# RA register map
Vendor: Renesas; Series: All Chips; File version: x.xx
Registers are 32-bit, read-write, reset 0x0 unless marked. A register's access mark holds for its fields unless they carry their own. Offsets are from the block's base; [hi:lo] are bit positions; lines under a group give offsets from that group; {n}, {i} and the like mark numbered series; 'fields as' and 'values as' point back to an identical list; <NAME> marks a mode.

## R_CANFD — Controller Area Network - Flexible Data (CAN-FD) Module
Base 0x400B0000
{0x0+0x10*i} CFDC[{i}] (i=0..1) group — Channel Control/Status
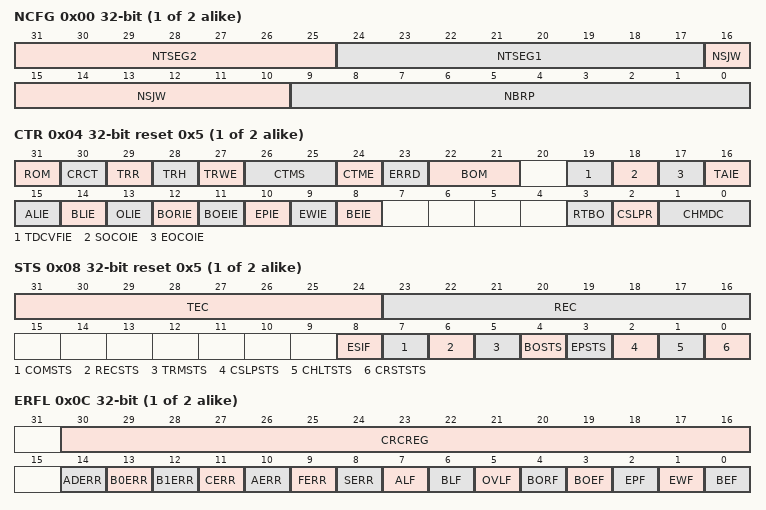
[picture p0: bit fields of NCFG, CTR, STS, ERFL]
  0x00 NCFG — Channel Nominal Bitrate Configuration Register
    [31:25] NTSEG2 — Timing Segment 2
    [24:17] NTSEG1 — Timing Segment 1
    [16:10] NSJW — Resynchronization Jump Width
    [9:0] NBRP — Channel Nominal Baud Rate Prescaler
  0x04 CTR reset 0x5 — Channel Control Registers
    [31] ROM — Restricted Operation Mode
      0=Restricted Operation Mode disabled; 1=Restricted Operation Mode enabled
    [30] CRCT — CRC Error Test
      0=First data bit of reception stream not inverted; 1=First data bit of reception stream inverted
    [29] TRR — TEC/REC Reset
      0=Error counter normal operation; 1=Error counter reset
    [28] TRH — TEC/REC Hold
      0=Error counter normal operation; 1=Error counter frozen
    [27] TRWE — TEC/REC Write Enable
      0=Error Counter write disabled; 1=Error Counter write enabled
    [26:25] CTMS — Channel Test Mode Select
      0=Basic test mode; 1=Listen-Only mode; 2=Self test mode 0 (External Loop back mode); 3=Self test mode 1 (Internal Loop back mode)
    [24] CTME — Channel Test Mode Enable
      0=Channel Test Mode disabled; 1=Channel Test Mode enabled
    [23] ERRD — Channel Error Display
      0=Only the 1st set of error codes displayed; 1=Accumulated error codes displayed
    [22:21] BOM — Channel Bus-Off Mode
      0=Normal mode (comply with ISO 11898-1); 1=Entry to Halt Mode automatically at Bus-Off start; 2=Entry to Halt Mode automatically at Bus-Off end; 3=Entry to Halt Mode (during Bus-Off Recovery Period) by S/W
    [19] TDCVFIE — Transceiver Delay Compensation Violation Interrupt enable
      0=Transceiver Delay Compensation Violation Interrupt disabled; 1=Transceiver Delay Compensation Violation Interrupt enabled
    [18] SOCOIE — Successful Occurrence Counter Overflow Interrupt enable
      0=Successful occurrence counter overflow interrupt disabled; 1=Successful occurrence counter overflow interrupt enabled
    [17] EOCOIE — Error occurrence counter overflow Interrupt enable
      0=Error occurrence counter overflow Interrupt disabled; 1=Error occurrence counter overflow Interrupt enabled
    [16] TAIE — Transmission abort Interrupt Enable
      0=TX abort Interrupt disabled; 1=TX abort Interrupt enabled
    [15] ALIE — Arbitration Lost Interrupt Enable
      0=Arbitration Lost Interrupt disabled; 1=Arbitration Lost Interrupt enabled
    [14] BLIE — Bus Lock Interrupt Enable
      0=Bus Lock Interrupt disabled; 1=Bus Lock Interrupt enabled
    [13] OLIE — Overload Interrupt Enable
      0=Overload Interrupt disabled; 1=Overload Interrupt enabled
    [12] BORIE — Bus-Off Recovery Interrupt Enable
      0=Bus-Off Recovery Interrupt disabled; 1=Bus-Off Recovery Interrupt enabled
    [11] BOEIE — Bus-Off Entry Interrupt Enable
      0=Bus-Off Entry Interrupt disabled; 1=Bus-Off Entry Interrupt enabled
    [10] EPIE — Error Passive Interrupt Enable
      0=Error Passive Interrupt disabled; 1=Error Passive Interrupt enabled
    [9] EWIE — Error Warning Interrupt Enable
      0=Error Warning Interrupt disabled; 1=Error Warning Interrupt enabled
    [8] BEIE — Bus Error Interrupt Enable
      0=Bus Error Interrupt disabled; 1=Bus Error Interrupt enabled
    [3] RTBO — Return from Bus-Off
      0=Channel is not forced to return from Bus-Off; 1=Channel is forced to return from Bus-Off
    [2] CSLPR — Channel Sleep Request
      0=Channel Sleep Request disabled; 1=Channel Sleep Request enabled
    [1:0] CHMDC — Channel Mode Control
      0=Channel Operation Mode request; 1=Channel Reset request; 2=Channel Halt request; 3=Keep current value
  0x08 STS reset 0x5 — Channel Status Registers
    [31:24] TEC — Transmission Error Count
    [23:16] REC ro — Reception Error Count
    [8] ESIF — Error State Indication Flag
      0=No CAN-FD message has been received with the ESI flag was set; 1=At least 1 CAN-FD message was received where the ESI flag was set
    [7] COMSTS ro — Channel Communication Status
      0=Channel is not ready for communication; 1=Channel is ready for communication
    [6] RECSTS ro — Channel Receive Status
      0=Channel is not receiving; 1=Channel is receiving
    [5] TRMSTS ro — Channel Transmit Status
      0=Channel is not transmitting; 1=Channel is transmitting
    [4] BOSTS ro — Channel Bus-Off Status
      0=Channel not in Bus-Off state; 1=Channel in Bus-Off state
    [3] EPSTS ro — Channel Error Passive Status
      0=Channel not in Error Passive state; 1=Channel in Error Passive state
    [2] CSLPSTS ro — Channel SLEEP Status
      0=Channel not in Sleep Mode; 1=Channel in Sleep Mode
    [1] CHLTSTS ro — Channel HALT Status
      0=Channel not in Halt Mode; 1=Channel in Halt Mode
    [0] CRSTSTS ro — Channel RESET Status
      0=Channel not in Reset Mode; 1=Channel in Reset Mode
  0x0C ERFL — Channel Error Flag Registers
    [30:16] CRCREG ro — CRC Register value
    [14] ADERR — Acknowledge Delimiter Error
      0=Channel Ack Del Error not detected; 1=Channel Ack Del Error detected
    [13] B0ERR — Bit 0 Error
      0=Channel Bit 0 Error not detected; 1=Channel Bit 0 Error detected
    [12] B1ERR — Bit 1 Error
      0=Channel Bit 1 Error not detected; 1=Channel Bit 1 Error detected
    [11] CERR — CRC Error
      0=Channel CRC Error not detected; 1=Channel CRC Error detected
    [10] AERR — Acknowledge Error
      0=Channel Ack Error not detected; 1=Channel Ack Error detected
    [9] FERR — Form Error
      0=Channel Form Error not detected; 1=Channel Form Error detected
    [8] SERR — Stuff Error
      0=Channel stuff Error not detected; 1=Channel stuff Error detected
    [7] ALF — Arbitration Lost Flag
      0=Channel Arbitration Lost not detected; 1=Channel Arbitration Lost detected
    [6] BLF — Bus Lock Flag
      0=Channel Bus Lock not detected; 1=Channel Bus Lock detected
    [5] OVLF — Overload Flag
      0=Channel Overload not detected; 1=Channel Overload detected
    [4] BORF — Bus-Off Recovery Flag
      0=Channel Bus-Off Recovery not detected; 1=Channel Bus-Off Recovery detected
    [3] BOEF — Bus-Off Entry Flag
      0=Channel Bus-Off Entry not detected; 1=Channel Bus-Off Entry detected
    [2] EPF — Error Passive Flag
      0=Channel Error Passive not detected; 1=Channel Error Passive detected
    [1] EWF — Error Warning Flag
      0=Channel Error Warning not detected; 1=Channel Error Warning detected
    [0] BEF — Bus Error Flag
      0=Channel Bus Error not detected; 1=Channel Bus Error detected
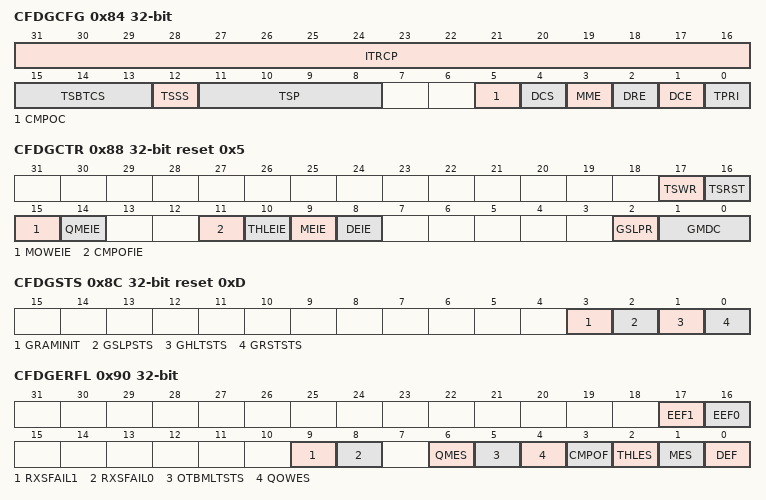
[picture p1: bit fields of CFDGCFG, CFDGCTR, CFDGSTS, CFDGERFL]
0x84 CFDGCFG — Global Configuration Register
  [31:16] ITRCP — Interval Timer Reference Clock Prescaler
  [15:13] TSBTCS — Timestamp Bit Time Channel Select
    0=select clock from Channel 0; 1=select clock from Channel 1; other=Others (Setting prohibited)
  [12] TSSS — Timestamp Source Select
    0=Source clock for Timestamp counter is peripheral clock; 1=Source clock for Timestamp counter is bit time clock
  [11:8] TSP — Timestamp Prescaler
  [5] CMPOC — CAN-FD message Payload overflow configuration
    0=Message is rejected; 1=Message payload is cut to fit to configured message size
  [4] DCS — Data Link Controller Clock Select
    0=Internal clean clock; 1=External Clock source connected to CANMCLK pin
  [3] MME — Mirror Mode Enable
    0=Mirror Mode disabled; 1=Mirror Mode enabled
  [2] DRE — DLC Replacement Enable
    0=DLC replacement disabled; 1=DLC replacement enabled
  [1] DCE — DLC Check Enable
    0=DLC check disabled; 1=DLC check enabled
  [0] TPRI — Transmission Priority
    0=ID Priority; 1=Message Buffer Number Priority
0x88 CFDGCTR reset 0x5 — Global Control Register
  [17] TSWR — Timestamp Write
    0=Timestamp write disabled; 1=Timestamp write enabled
  [16] TSRST — Timestamp Reset
    0=Timestamp not reset; 1=Timestamp reset
  [15] MOWEIE — GW FIFO Message overwrite Error Interrupt Enable
    0=GW FIFO Message overwrite Error Interrupt Disabled; 1=GW FIFO Message overwrite Error Interrupt Enabled
  [14] QMEIE — TXQ Message lost Error Interrupt Enable
    0=TXQ Message Lost Error Interrupt Disabled; 1=TXQ Message Lost Error Interrupt Enabled
  [11] CMPOFIE — CAN-FD message payload overflow Flag Interrupt enable
    0=CAN-FD message payload overflow Flag Interrupt Disabled; 1=CAN-FD message payload overflow Flag Interrupt Enabled
  [10] THLEIE — TX History List Entry Lost Interrupt Enable
    0=TX History List Entry Lost Interrupt Disabled; 1=TX History List Entry Lost Interrupt Enabled
  [9] MEIE — Message lost Error Interrupt Enable
    0=Message Lost Error Interrupt Disabled; 1=Message Lost Error Interrupt Enabled
  [8] DEIE — DLC check Interrupt Enable
    0=DLC check Interrupt Disabled; 1=DLC check Interrupt Enabled
  [2] GSLPR — Global Sleep Request
    0=Global Sleep Request Disabled; 1=Global Sleep Request Enabled
  [1:0] GMDC — Global Mode Control
    0=Global Operation Mode Request; 1=Global Reset Mode Request; 2=Global Halt Mode Request; 3=Keep Current Value
0x8C CFDGSTS reset 0xD — Global Status Register
  [3] GRAMINIT ro — Global RAM Initialisation
    0=RAM initialisation is finished; 1=RAM initialisation ongoing
  [2] GSLPSTS ro — Global Sleep Status
    0=Not in Sleep Mode; 1=In Sleep Mode
  [1] GHLTSTS ro — Global Halt Status
    0=Not in Halt Mode; 1=In Halt Mode
  [0] GRSTSTS ro — Global Reset Status
    0=Not in Reset Mode; 1=In Reset Mode
0x90 CFDGERFL — Global Error Flag Register
  [17] EEF1 — ECC Error Flag for Channel 1
    0=ECC Error not detected during TX-SCAN; 1=ECC Error detected during TX-SCAN
  [16] EEF0 — ECC Error Flag for Channel 0
    values as EEF1
  [9] RXSFAIL1 — RX Scan Fail of Channel 1
    0=RX Scan fail not detected; 1=RX Scan fail detected
  [8] RXSFAIL0 — RX Scan Fail of Channel 0
    0=RX Scan fail not detected; 1=RX Scan fail detected
  [6] QMES ro — TXQ Message Lost Error Status
    0=TXQ Message lost Error not detected; 1=TXQ Message lost Error detected
  [5] OTBMLTSTS ro — OTB FIFO Message Lost Status
    0=Message lost Error not detected; 1=Message lost Error detected
  [4] QOWES ro — TXQ Message overwrite Error Status
    0=TXQ Message overwrite Error not detected; 1=TXQ Message overwrite Error detected
  [3] CMPOF — CAN-FD message payload overflow Flag
    0=CAN-FD message payload overflow not detected; 1=CAN-FD message payload overflow detected
  [2] THLES ro — TX History List Entry Lost Error Status
    0=TX History List Entry Lost Error not detected; 1=TX History List Entry Lost Error detected
  [1] MES ro — Message Lost Error Status
    values as OTBMLTSTS
  [0] DEF — DLC Error Flag
    0=DLC Error not detected; 1=DLC Error detected
0x94 CFDGTSC — Global Timestamp Counter Register
  [15:0] TS ro — Timestamp Value
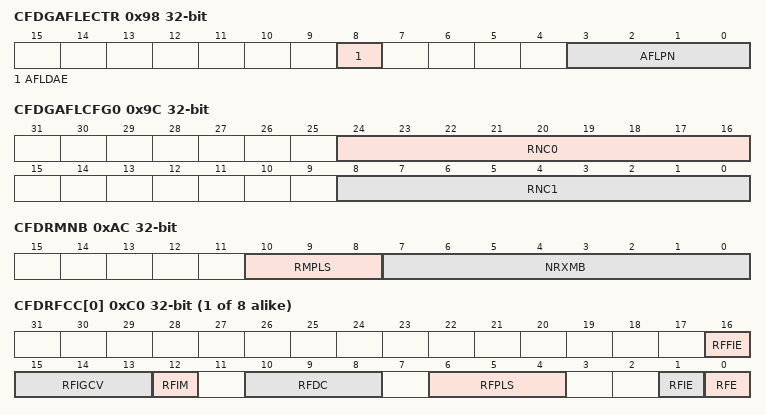
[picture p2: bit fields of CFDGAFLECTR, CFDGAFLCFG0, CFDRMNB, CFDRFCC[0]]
0x98 CFDGAFLECTR — Global Acceptance Filter List Entry Control Register
  [8] AFLDAE — Acceptance Filter List Data Access Enable
    0=Acceptance Filter List Data access disabled; 1=Acceptance Filter List Data access enabled
  [3:0] AFLPN — Acceptance Filter List Page Number
0x9C CFDGAFLCFG0 — Global Acceptance Filter List Configuration Register 0
  [24:16] RNC0 — Rule Number for Channel 0
  [8:0] RNC1 — Rule Number for Channel 1
0xAC CFDRMNB — RX Message Buffer Number Register
  [10:8] RMPLS — Reception Message Buffer Payload Data Size
    0=8 Bytes; 1=12 Bytes; 2=16 Bytes; 3=20 Bytes; 4=24 Bytes; 5=32 Bytes; 6=48 Bytes; 7=64 Bytes
  [7:0] NRXMB — Number of RX Message Buffers
0xB0 CFDRMND0 — RX Message Buffer New Data Register 0
  [31:0] RMNSu — RX Message Buffer New Data Status
    0=New Data not stored in corresponding RX Message Buffer; 1=New Data stored in corresponding RX Message Buffer
{0xC0+4i} CFDRFCC[{i}] (i=0..7) — RX FIFO Configuration / Control Registers
  [16] RFFIE — RX FIFO Full interrupt Enable
    0=FIFO Interrupt generation disabled; 1=FIFO Interrupt generation enabled
  [15:13] RFIGCV — RX FIFO Interrupt Generation Counter Value
    0=Interrupt generated when FIFO is 1/8th Full; 1=Interrupt generated when FIFO is 1/4th Full; 2=Interrupt generated when FIFO is 3/8th Full; 3=Interrupt generated when FIFO is 1/2 Full; 4=Interrupt generated when FIFO is 5/8th Full; 5=Interrupt generated when FIFO is 3/4th Full; 6=Interrupt generated when FIFO is 7/8th Full; 7=Interrupt generated when FIFO is Full
  [12] RFIM — RX FIFO Interrupt Mode
    0=Interrupt generated when RX FIFO counter reaches RFIGCV value from values smaller than RFIGCV; 1=Interrupt generated at the end of every received message storage
  [10:8] RFDC — RX FIFO Depth Configuration
    0=FIFO Depth = 0 Messages; 1=FIFO Depth = 4 Messages; 2=FIFO Depth = 8 Messages; 3=FIFO Depth = 16 Messages; 4=FIFO Depth = 32 Messages; 5=FIFO Depth = 48 Messages; 6=FIFO Depth = 64 Messages; 7=FIFO Depth = 128 Messages
  [6:4] RFPLS — Rx FIFO Payload Data Size configuration
    values as CFDRMNB.RMPLS
  [1] RFIE — RX FIFO Interrupt Enable
    values as RFFIE
  [0] RFE — RX FIFO Enable
    0=FIFO disabled; 1=FIFO enabled
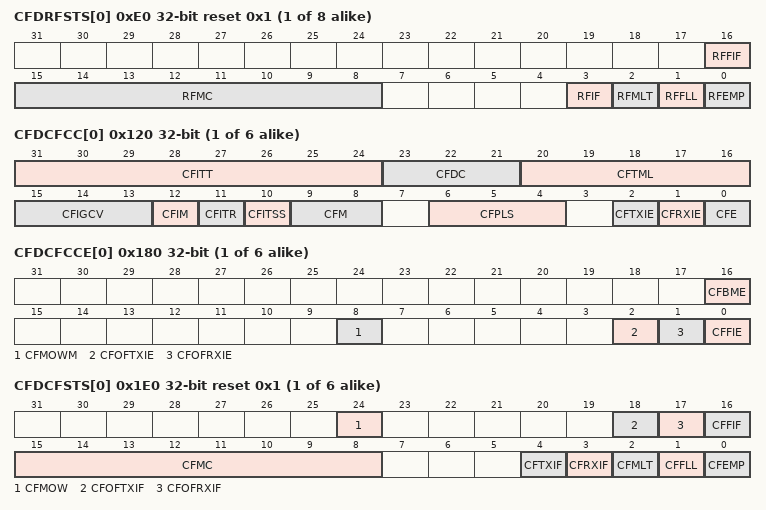
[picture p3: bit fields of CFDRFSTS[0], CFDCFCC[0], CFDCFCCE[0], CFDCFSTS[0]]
{0xE0+4i} CFDRFSTS[{i}] (i=0..7) reset 0x1 — RX FIFO Status Registers
  [16] RFFIF — RX FIFO Full Interrupt Flag
    0=FIFO Full interrupt condition not satisfied; 1=FIFO Full interrupt condition satisfied
  [15:8] RFMC ro — RX FIFO Message Count
  [3] RFIF — RX FIFO Interrupt Flag
    0=FIFO Interrupt condition not satisfied; 1=FIFO Interrupt condition satisfied
  [2] RFMLT — RX FIFO Message Lost
    0=No Message Lost in FIFO; 1=FIFO Message Lost
  [1] RFFLL ro — RX FIFO Full
    0=FIFO Not Full; 1=FIFO Full
  [0] RFEMP ro — RX FIFO Empty
    0=FIFO Not Empty; 1=FIFO Empty
{0x100+4i} CFDRFPCTR[{i}] (i=0..7) — RX FIFO Pointer Control Registers
  [7:0] RFPC wo — RX FIFO Pointer Control
{0x120+4i} CFDCFCC[{i}] (i=0..5) — Common FIFO Configuration / Control Registers
  [31:24] CFITT — Common FIFO Interval Transmission Time
  [23:21] CFDC — Common FIFO Depth Configuration
    values as CFDRFCC[0].RFDC
  [20:16] CFTML — Common FIFO TX Message Buffer Link
  [15:13] CFIGCV — Common FIFO Interrupt Generation Counter Value
    values as CFDRFCC[0].RFIGCV
  [12] CFIM — Common FIFO Interrupt Mode
    0=RX FIFO Mode: RX Interrupt generated when Common FIFO counter reaches CFIGCV value from a lower value TX FIFO Mode: TX Interrupt generated when Common FIFO transmits the last message successfully GW FIFO Mode: For RX interrupt flag: Interrupt generated when FIFO counter increments and reaches the value configured in CFIGCV For TX interrupt flag: Interrupt generated when FIFO transmits the last message successfully; 1=RX FIFO Mode: RX Interrupt generated at the end of every received message storage TX FIFO Mode: Interrupt generated for every successfully transmitted message GW FIFO Mode: For RX interrupt flag: Interrupt generated when a message is stored in the FIFO For TX interrupt flag: Interrupt generated when a message is successfully transmitted from the FIFO
  [11] CFITR — Common FIFO Interval Timer Resolution
    0=Reference Clock Period x1; 1=Reference Clock Period x10
  [10] CFITSS — Common FIFO Interval Timer Source Select
    0=Reference Clock (x1 / x10 period); 1=Bit Time Clock of related channel (FIFO is linked to fixed channel)
  [9:8] CFM — Common FIFO Mode
    0=RX FIFO Mode; 1=TX FIFO Mode; 2=CAN - CAN GW FIFO Mode
  [6:4] CFPLS — Common FIFO Payload Data size configuration
    0=8 bytes; 1=12 bytes; 2=16 bytes; 3=20 bytes; 4=24 bytes; 5=32 bytes; 6=48 bytes; 7=64 bytes
  [2] CFTXIE — Common FIFO TX Interrupt Enable
    0=FIFO Interrupt generation disabled for Frame TX; 1=FIFO Interrupt generation enabled for Frame TX
  [1] CFRXIE — Common FIFO RX Interrupt Enable
    0=FIFO Interrupt generation disabled for Frame RX; 1=FIFO Interrupt generation enabled for Frame RX
  [0] CFE — Common FIFO Enable
    0=FIFO disabled; 1=FIFO enabled
{0x180+4i} CFDCFCCE[{i}] (i=0..5) — Common FIFO Configuration / Control Enhancement Registers
  [16] CFBME — Common FIFO Buffering Mode Enable
    0=Transmission from Common FIFO; 1=Transmission halt from Common FIFO
  [8] CFMOWM — Common FIFO message overwrite mode
    0=Message discarded mode; 1=Message overwrite mode
  [2] CFOFTXIE — Common FIFO One Frame Transmission Interrupt Enable
    0=One Frame TX Interrupt generation disabled; 1=One Frame TX Interrupt generation enabled
  [1] CFOFRXIE — Common FIFO One Frame Reception Interrupt Enable
    0=One Frame RX Interrupt generation disabled; 1=One Frame RX Interrupt generation enabled
  [0] CFFIE — Common FIFO Full interrupt Enable
    values as CFDRFCC[0].RFFIE
{0x1E0+4i} CFDCFSTS[{i}] (i=0..5) reset 0x1 — Common FIFO Status Registers
  [24] CFMOW — Common FIFO message overwrite
    0=No Message overwrite occurred in FIFO; 1=Message overwrite occurred in FIFO
  [18] CFOFTXIF — Common FIFO One Frame Transmission Interrupt Flag
  [17] CFOFRXIF — Common FIFO One Frame Reception Interrupt Flag
  [16] CFFIF — Common FIFO Full Interrupt Flag
    0=Interrupt condition not satisfied for FIFO Full interrupt; 1=Interrupt condition satisfied for FIFO Full interrupt
  [15:8] CFMC ro — Common FIFO Message Count
  [4] CFTXIF — Common TX FIFO Interrupt Flag
    0=FIFO Interrupt condition not satisfied after Frame Transmission; 1=FIFO Interrupt condition satisfied after Frame Transmission
  [3] CFRXIF — Common RX FIFO Interrupt Flag
    0=FIFO Interrupt condition not satisfied after Frame Reception; 1=FIFO Interrupt condition satisfied after Frame Reception
  [2] CFMLT — Common FIFO Message Lost
    0=No Message Lost in FIFO; 1=FIFO Message Lost
  [1] CFFLL ro — Common FIFO Full
    0=FIFO Not Full; 1=FIFO Full
  [0] CFEMP ro — Common FIFO Empty
    0=FIFO Not Empty; 1=FIFO Empty
{0x240+4i} CFDCFPCTR[{i}] (i=0..5) — Common FIFO Pointer Control Registers
  [7:0] CFPC wo — Common FIFO Pointer Control
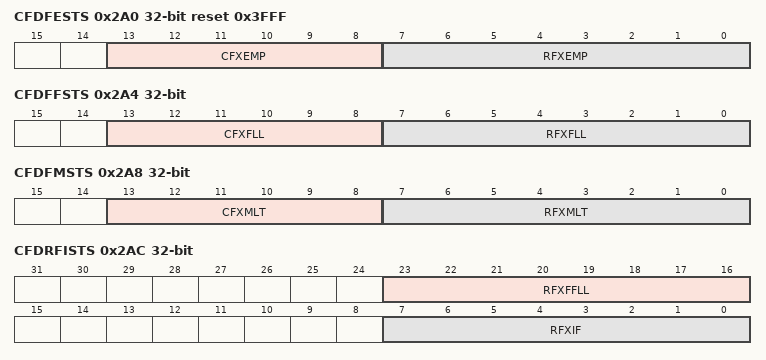
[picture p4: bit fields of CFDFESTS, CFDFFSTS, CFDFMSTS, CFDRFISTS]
0x2A0 CFDFESTS ro reset 0x3FFF — FIFO Empty Status Register
  [13:8] CFXEMP — Common FIF0 Empty Status
    0=Corresponding FIFO not Empty; 1=Corresponding FIFO Empty
  [7:0] RFXEMP — RX FIF0 Empty Status
    0=Corresponding FIFO not Empty; 1=Corresponding FIFO Empty
0x2A4 CFDFFSTS ro — FIFO Full Status Register
  [13:8] CFXFLL — Common FIF0 Full Status
    0=Corresponding FIFO not Full; 1=Corresponding FIFO Full
  [7:0] RFXFLL — RX FIF0 Full Status
    0=Corresponding FIFO not Full; 1=Corresponding FIFO Full
0x2A8 CFDFMSTS ro — FIFO Message Lost Status Register
  [13:8] CFXMLT — Common FIFO Msg Lost Status
    0=Corresponding FIFO Msg Lost flag not set; 1=Corresponding FIFO Msg Lost flag set
  [7:0] RFXMLT — RX FIFO Msg Lost Status
    values as CFXMLT
0x2AC CFDRFISTS — RX FIFO Interrupt Flag Status Register
  [23:16] RFXFFLL ro — RX FIFO[x] Interrupt Full Flag Status
    0=Corresponding RX FIFO interrupt Full flag not set; 1=Corresponding RX FIFO interrupt Full flag set
  [7:0] RFXIF ro — RX FIFO[x] Interrupt Flag Status
    0=Corresponding RX FIFO interrupt flag not set; 1=Corresponding RX FIFO interrupt flag set
0x2B0 CFDCFRISTS — Common FIFO RX Interrupt Flag Status Register
  [5:0] CFXRXIF ro — Common FIFO [x] RX Interrupt Flag Status
    0=Corresponding Common FIFO RX interrupt flag is not set; 1=Corresponding Common FIFO RX interrupt flag is set
0x2B4 CFDCFTISTS — Common FIFO TX Interrupt Flag Status Register
  [5:0] CFXTXIF ro — Common FIFO [x] TX Interrupt Flag Status
    0=Corresponding Common FIFO TX interrupt flag is not set; 1=Corresponding Common FIFO TX interrupt flag is set
0x2B8 CFDCFOFRISTS ro — Common FIFO One Frame RX Interrupt Flag Status Register
  [5:0] CFXOFRXIF — Common FIFO [x] One Frame RX Interrupt Flag Status
    0=Corresponding Common FIFO One Frame RX interrupt flag is not set; 1=Corresponding Common FIFO One Frame RX interrupt flag is set
0x2BC CFDCFOFTISTS ro — Common FIFO One Frame TX Interrupt Flag Status Register
  [5:0] CFXOFTXIF — Common FIFO [x] One Frame TX Interrupt Flag Status
    0=Corresponding Common FIFO One Frame TX interrupt flag is not set; 1=Corresponding Common FIFO One Frame TX interrupt flag is set
0x2C0 CFDCFMOWSTS ro — Common FIFO Message Over Write Status Register
  [5:0] CFXMOW — Common FIFO [x] Massage overwrite status
    0=Corresponding FIFO overwrite flag is not set; 1=Corresponding FIFO overwrite flag is set
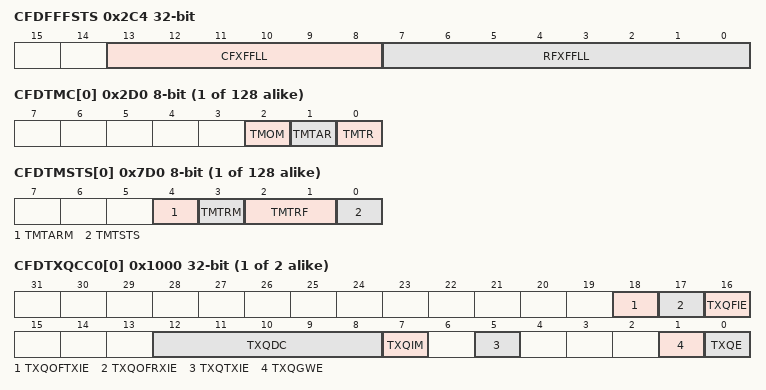
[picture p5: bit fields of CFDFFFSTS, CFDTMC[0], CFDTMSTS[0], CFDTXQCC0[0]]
0x2C4 CFDFFFSTS ro — FIFO FDC Full Status Register
  [13:8] CFXFFLL — COMMON FIFO FDC level full Status
    0=Corresponding FIFO Full interrupt not set; 1=Corresponding FIFO Full interrupt is set
  [7:0] RFXFFLL — RX FIFO FDC level full Status
    values as CFXFFLL
{0x2D0+i} CFDTMC[{i}] (i=0..127) 8-bit — TX Message Buffer Control Registers
  [2] TMOM — TX Message Buffer One-shot Mode
    0=TX Message Buffer not configured in one-shot mode; 1=TX Message Buffer configured in one-shot mode
  [1] TMTAR — TX Message Buffer Transmission abort Request
    0=TX Message Buffer transmission request abort not requested; 1=TX Message Buffer transmission request abort requested
  [0] TMTR — TX Message Buffer Transmission Request
    0=TX Message Buffer Transmission not requested; 1=TX Message Buffer Transmission requested
{0x7D0+i} CFDTMSTS[{i}] (i=0..127) 8-bit — TX Message Buffer Status Registers
  [4] TMTARM ro — TX Message Buffer Transmission abort Request Mirrored
    values as CFDTMC[0].TMTAR
  [3] TMTRM ro — TX Message Buffer Transmission Request Mirrored
    values as CFDTMC[0].TMTR
  [2:1] TMTRF — TX Message Buffer Transmission Result Flag
    0=No Result; 1=Transmission aborted from the TX MB; 2=Transmission successful from the TX MB & Transmission abort was not requested; 3=Transmission successful from the TX MB & Transmission abort was requested
  [0] TMTSTS ro — TX Message Buffer Transmission Status
    0=No transmission ongoing; 1=Transmission ongoing
{0xCD0+4i} CFDTMTRSTS[{i}] (i=0..3) ro — TX Message Buffer Transmission Request Status Register
  [7:0] CFDTMTRSTSg — TX Message Buffer Transmission Request Status
    0=Transmission not requested for corresponding TX Message Buffer; 1=Transmission requested for corresponding TX Message Buffer
{0xD70+4i} CFDTMTARSTS[{i}] (i=0..3) ro — TX Message Buffer Transmission Abort Request Status Register
  [7:0] CFDTMTARSTSg — TX Message Buffer Transmission abort Request Status
    0=Transmission abort not requested for corresponding TX Message Buffer; 1=Transmission abort requested for corresponding TX Message Buffer
{0xE10+4i} CFDTMTCSTS[{i}] (i=0..3) ro — TX Message Buffer Transmission Completion Status Register
  [7:0] CFDTMTCSTSg — TX Message Buffer Transmission Completion Status
    0=Transmission not complete for corresponding TX Message Buffer; 1=Transmission completed for corresponding TX Message Buffer
{0xEB0+4i} CFDTMTASTS[{i}] (i=0..3) ro — TX Message Buffer Transmission Abort Status Register
  [7:0] CFDTMTASTSg — TX Message Buffer Transmission abort Status
    0=Transmission not aborted for corresponding TX Message Buffer; 1=Transmission aborted for corresponding TX Message Buffer
{0xF50+4i} CFDTMIEC[{i}] (i=0..3) — TX Message Buffer Interrupt Enable Configuration Register
  [7:0] TMIEg — TX Message Buffer Interrupt Enable
    0=TX Message Buffer Interrupt disabled for corresponding TX message buffer; 1=TX Message Buffer Interrupt enabled for corresponding TX message buffer
{0x1000+4i} CFDTXQCC0[{i}] (i=0..1) — TX Queue Configuration / Control Registers 0
  [18] TXQOFTXIE — TXQ One Frame Transmission Interrupt Enable
    values as CFDCFCCE[0].CFOFTXIE
  [17] TXQOFRXIE — TXQ One Frame Reception Interrupt Enable
    values as CFDCFCCE[0].CFOFRXIE
  [16] TXQFIE — TXQ Full interrupt Enable
    0=TX Queue Full Interrupt generation disabled; 1=TX Queue Full Interrupt generation enabled
  [12:8] TXQDC — TX Queue Depth Configuration
  [7] TXQIM — TX Queue Interrupt Mode
    0=When the last message is successfully transmitted; 1=At every successful transmission
  [5] TXQTXIE — TX Queue TX Interrupt Enable
    0=TX Queue TX Interrupt disabled; 1=TX Queue TX Interrupt enabled
  [1] TXQGWE — TX Queue Gateway Mode Enable
    0=TX Queue GW mode disabled; 1=TX Queue GW mode enabled
  [0] TXQE — TX Queue Enable
    0=TX Queue disabled; 1=TX Queue enabled
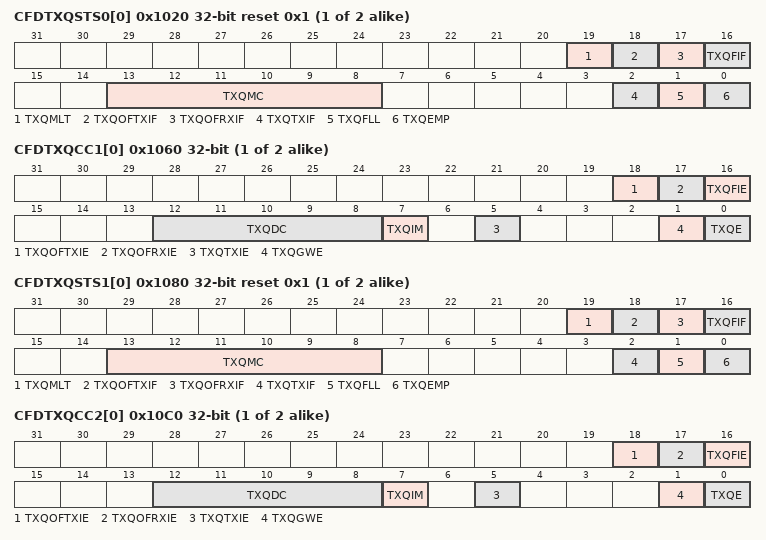
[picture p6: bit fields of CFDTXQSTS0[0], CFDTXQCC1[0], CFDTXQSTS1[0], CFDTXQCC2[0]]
{0x1020+4i} CFDTXQSTS0[{i}] (i=0..1) reset 0x1 — TX Queue Status Registers 0
  [19] TXQMLT — TXQ Message Lost
    0=No Message Lost in TXQ; 1=TXQ Message Lost
  [18] TXQOFTXIF — TXQ One Frame Transmission Interrupt Flag
  [17] TXQOFRXIF — TXQ One Frame Reception Interrupt Flag
  [16] TXQFIF — TXQ Full Interrupt Flag
  [13:8] TXQMC ro — TX Queue Message Count
  [2] TXQTXIF — TX Queue TX Interrupt Flag
    0=TX Queue interrupt condition not satisfied after Frame TX; 1=TX Queue interrupt condition satisfied after Frame TX
  [1] TXQFLL ro — TX Queue Full
    0=TX Queue Not Full; 1=TX Queue Full
  [0] TXQEMP ro — TX Queue Empty
    0=TX Queue Not Empty; 1=TX Queue Empty
{0x1040+4i} CFDTXQPCTR0[{i}] (i=0..1) — TX Queue Pointer Control Registers 0
  [7:0] TXQPC wo — TX Queue Pointer Control
{0x1060+4i} CFDTXQCC1[{i}] (i=0..1) — TX Queue Configuration / Control Registers 1
  [18] TXQOFTXIE — TXQ One Frame Transmission Interrupt Enable
    values as CFDCFCCE[0].CFOFTXIE
  [17] TXQOFRXIE — TXQ One Frame Reception Interrupt Enable
    values as CFDCFCCE[0].CFOFRXIE
  [16] TXQFIE — TXQ Full Interrupt Enable
    values as CFDTXQCC0[0].TXQFIE
  [12:8] TXQDC — TX Queue Depth Configuration
  [7] TXQIM — TX Queue Interrupt Mode
    values as CFDTXQCC0[0].TXQIM
  [5] TXQTXIE — TX Queue TX Interrupt Enable
    values as CFDTXQCC0[0].TXQTXIE
  [1] TXQGWE — TX Queue Gateway Mode Enable
    0=TX Queue GW mode disabled; 1=TX Queue GW mode enabled
  [0] TXQE — TX Queue Enable
    0=TX Queue disabled; 1=TX Queue enabled
{0x1080+4i} CFDTXQSTS1[{i}] (i=0..1) reset 0x1 — TX Queue Status Registers 1
  fields as CFDTXQSTS0[0]
{0x10A0+4i} CFDTXQPCTR1[{i}] (i=0..1) — TX Queue Pointer Control Registers 1
  [7:0] TXQPC wo — TX Queue Pointer Control
{0x10C0+4i} CFDTXQCC2[{i}] (i=0..1) — TX Queue Configuration / Control Registers 2
  fields as CFDTXQCC0[0]
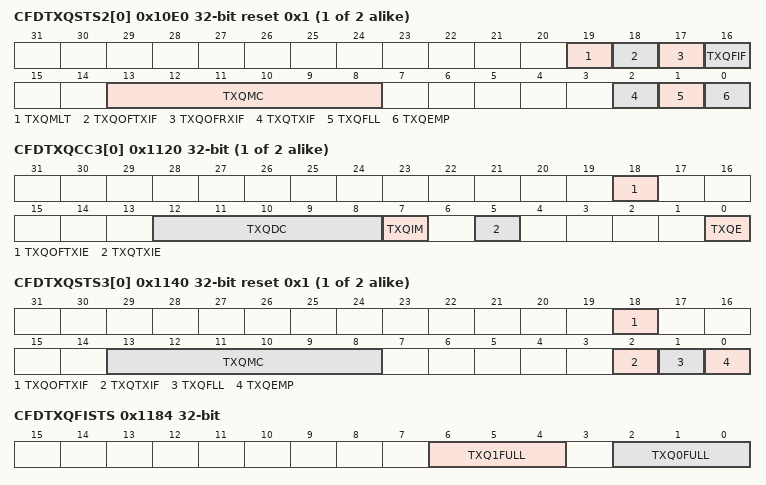
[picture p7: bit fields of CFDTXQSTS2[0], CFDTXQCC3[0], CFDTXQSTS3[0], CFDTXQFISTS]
{0x10E0+4i} CFDTXQSTS2[{i}] (i=0..1) reset 0x1 — TX Queue Status Registers 2
  fields as CFDTXQSTS0[0]
{0x1100+4i} CFDTXQPCTR2[{i}] (i=0..1) — TX Queue Pointer Control Registers 2
  [7:0] TXQPC wo — TX Queue Pointer Control
{0x1120+4i} CFDTXQCC3[{i}] (i=0..1) — TX Queue Configuration / Control Registers 3
  [18] TXQOFTXIE — TXQ One Frame Transmission Interrupt Enable
    values as CFDCFCCE[0].CFOFTXIE
  [12:8] TXQDC — TX Queue Depth Configuration
  [7] TXQIM — TX Queue Interrupt Mode
    values as CFDTXQCC0[0].TXQIM
  [5] TXQTXIE — TX Queue TX Interrupt Enable
    values as CFDTXQCC0[0].TXQTXIE
  [0] TXQE — TX Queue Enable
    0=TX Queue disabled; 1=TX Queue enabled
{0x1140+4i} CFDTXQSTS3[{i}] (i=0..1) reset 0x1 — TX Queue Status Registers 3
  [18] TXQOFTXIF — TXQ One Frame Transmission Interrupt Flag
  [13:8] TXQMC ro — TX Queue Message Count
  [2] TXQTXIF — TX Queue TX Interrupt Flag
    values as CFDTXQSTS0[0].TXQTXIF
  [1] TXQFLL ro — TX Queue Full
    0=TX Queue Not Full; 1=TX Queue Full
  [0] TXQEMP ro — TX Queue Empty
    0=TX Queue Not Empty; 1=TX Queue Empty
{0x1160+4i} CFDTXQPCTR3[{i}] (i=0..1) — TX Queue Pointer Control Registers 3
  [7:0] TXQPC wo — TX Queue Pointer Control
0x1180 CFDTXQESTS ro reset 0xFF — TX Queue Empty Status Register
  [7:0] TXQxEMP — TXQ empty Status
    0=TXQ not empty; 1=TXQ empty
0x1184 CFDTXQFISTS — TX Queue Full Interrupt Status Register
  [6:4] TXQ1FULL ro — TXQ Full Interrupt Status for channel 1
    0=TXQ Full Interrupt is not set; 1=TXQ Full Interrupt is set
  [2:0] TXQ0FULL ro — TXQ Full Interrupt Status for channel 0
    0=TXQ Full Interrupt is not set; 1=TXQ Full Interrupt is set
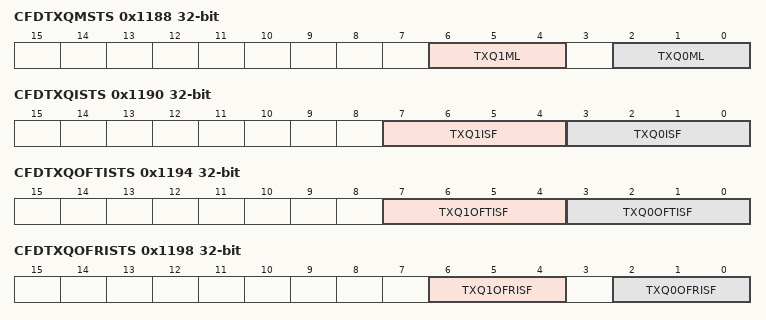
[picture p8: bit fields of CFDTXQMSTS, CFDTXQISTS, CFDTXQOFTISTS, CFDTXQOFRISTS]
0x1188 CFDTXQMSTS — TX Queue Message Lost Status Register
  [6:4] TXQ1ML ro — TXQ message lost Status for channel 1
    0=TXQ message lost flag is not set; 1=TXQ message lost flag is set
  [2:0] TXQ0ML ro — TXQ message lost Status for channel 0
    values as TXQ1ML
0x1190 CFDTXQISTS — TX Queue Interrupt Status Register
  [7:4] TXQ1ISF ro — TXQ Interrupt Status Flag for channel 1
    0=TXQ Interrupt flag is not set; 1=TXQ Interrupt flag is set
  [3:0] TXQ0ISF ro — TXQ Interrupt Status Flag for channel 0
    0=TXQ Interrupt flag is not set; 1=TXQ Interrupt flag is set
0x1194 CFDTXQOFTISTS — TX Queue One Frame TX Interrupt Status Register
  [7:4] TXQ1OFTISF ro — TXQ One Frame TX Interrupt Status Flag for channel 1
    0=TXQ One Frame TX Interrupt flag is not set; 1=TXQ One Frame TX Interrupt flag is set
  [3:0] TXQ0OFTISF ro — TXQ One Frame TX Interrupt Status Flag for channel 0
    values as TXQ1OFTISF
0x1198 CFDTXQOFRISTS — TX Queue One Frame RX Interrupt Status Register
  [6:4] TXQ1OFRISF ro — TXQ One Frame RX Interrupt Status Flag
    0=TXQ One Frame RX Interrupt flag is not set; 1=TXQ One Frame RX Interrupt flag is set
  [2:0] TXQ0OFRISF ro — TXQ One Frame RX Interrupt Status Flag
    values as TXQ1OFRISF
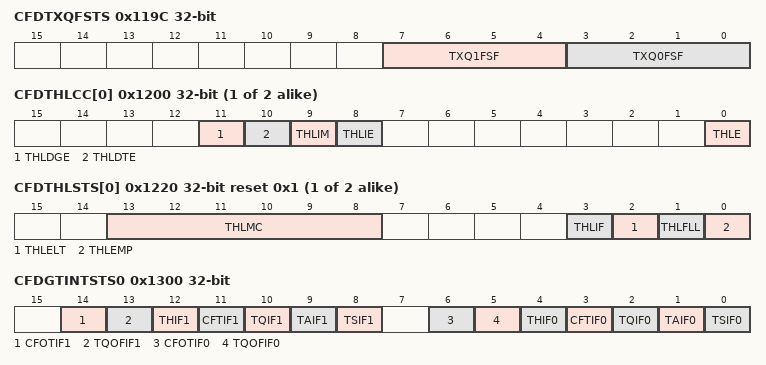
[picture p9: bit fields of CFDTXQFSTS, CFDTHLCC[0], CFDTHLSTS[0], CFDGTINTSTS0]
0x119C CFDTXQFSTS ro — TX Queue Full Status Register
  [7:4] TXQ1FSF — TXQ Full Status Flag for channel 1
    0=TXQ Full flag is not set; 1=TXQ Full flag is set
  [3:0] TXQ0FSF — TXQ Full Status Flag for channel 0
    0=TXQ Full flag is not set; 1=TXQ Full flag is set
{0x1200+4i} CFDTHLCC[{i}] (i=0..1) — TX History List Configuration / Control Register
  [11] THLDGE — TX History List Dedicated GW Enable
    0=Not dedicate Gateway FIFO + Gateway TX Queue; 1=Dedicate Gateway FIFO + Gateway TX Queue
  [10] THLDTE — TX History List Dedicated TX Enable
    0=TX FIFO + TX Queue; 1=Flat TX MB + TX FIFO + TX Queue
  [9] THLIM — TX History List Interrupt Mode
    0=Interrupt generated if TX History List level reaches 3/4 of the TX History List depth; 1=Interrupt generated for every successfully stored entry
  [8] THLIE — TX History List Interrupt Enable
    0=TX History List Interrupt disabled; 1=TX History List Interrupt enabled
  [0] THLE — TX History List Enable
    0=TX History List disabled; 1=TX History List enabled
{0x1220+4i} CFDTHLSTS[{i}] (i=0..1) reset 0x1 — TX History List Status Register
  [13:8] THLMC ro — TX History List Message Count
  [3] THLIF — TX History List Interrupt Flag
    0=TX History List Interrupt condition not satisfied; 1=TX History List Interrupt condition satisfied
  [2] THLELT — TX History List Entry Lost
    0=No Entry Lost in TX History List; 1=TX History List Entry Lost
  [1] THLFLL ro — TX History List Full
    0=TX History List Not Full; 1=TX History List Full
  [0] THLEMP ro — TX History List Empty
    0=TX History List Not Empty; 1=TX History List Empty
{0x1240+4i} CFDTHLPCTR[{i}] (i=0..1) — TX History List Pointer Control Registers
  [7:0] THLPC wo — TX History List Pointer Control
0x1300 CFDGTINTSTS0 — Global TX Interrupt Status Register 0
  [14] CFOTIF1 ro — COM FIFO One Frame Transmission Interrupt Flag Channel 1
    0=Channel n COM FIFO One Frame Transmission Interrupt flag not set; 1=Channel n COM FIFO One Frame Transmission Interrupt flag set
  [13] TQOFIF1 ro — TX Queue One Frame Transmission Interrupt Flag Channel 1
    0=Channel n TX Queue One Frame Transmission Interrupt flag not set; 1=Channel n TX Queue One Frame Transmission Interrupt flag set
  [12] THIF1 ro — TX History List Interrupt Channel 1
    0=Channel n TX History List Interrupt flag not set; 1=Channel n TX History List Interrupt flag set
  [11] CFTIF1 ro — COM FIFO TX/GW Mode Interrupt Flag Channel 1
    0=Channel n COM FIFO TX/GW mode Interrupt flag not set; 1=Channel n COM FIFO TX/GW mode Interrupt flag set
  [10] TQIF1 ro — TX Queue Interrupt Flag Channel 1
    0=Channel n TX Queue Interrupt flag not set; 1=Channel n TX Queue Interrupt flag set
  [9] TAIF1 ro — TX Abort Interrupt Flag Channel 1
    0=Channel n TX abort Interrupt flag not set; 1=Channel n TX abort Interrupt flag set
  [8] TSIF1 ro — TX Successful Interrupt Flag Channel 1
    0=Channel n TX Successful completion Interrupt flag not set; 1=Channel n TX Successful completion Interrupt flag set
  [6] CFOTIF0 ro — COM FIFO One Frame Transmission Interrupt Flag Channel 0
    values as CFOTIF1
  [5] TQOFIF0 ro — TX Queue One Frame Transmission Interrupt Flag Channel 0
    values as TQOFIF1
  [4] THIF0 ro — TX History List Interrupt Channel 0
    values as THIF1
  [3] CFTIF0 ro — COM FIFO TX/GW Mode Interrupt Flag Channel 0
    values as CFTIF1
  [2] TQIF0 ro — TX Queue Interrupt Flag Channel 0
    values as TQIF1
  [1] TAIF0 ro — TX Abort Interrupt Flag Channel 0
    values as TAIF1
  [0] TSIF0 ro — TX Successful Interrupt Flag Channel 0
    values as TSIF1
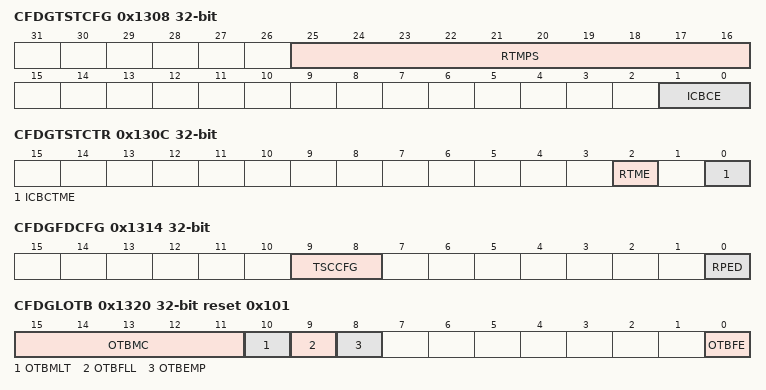
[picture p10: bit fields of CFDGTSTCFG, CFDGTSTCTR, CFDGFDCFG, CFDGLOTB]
0x1308 CFDGTSTCFG — Global Test Configuration Register
  [25:16] RTMPS — RAM Test Mode Page Select
  [1:0] ICBCE — Channel n Internal CAN Bus Communication Test Mode Enable
    0=Channel n internal CAN bus communication disabled; 1=Channel n internal CAN bus communication enabled
0x130C CFDGTSTCTR — Global Test Control Register
  [2] RTME — RAM Test Mode Enable
    0=RAM Test Mode disabled; 1=RAM Test Mode enabled
  [0] ICBCTME — Internal CAN Bus Communication Test Mode Enable
    0=Internal CAN Bus communication test mode disabled; 1=Internal CAN Bus communication test mode enabled
0x1314 CFDGFDCFG — Global FD Configuration register
  [9:8] TSCCFG — Timestamp capture configuration
    0=Timestamp capture at the sample point of SOF (start of frame); 1=Timestamp capture at frame valid indication; 2=Timestamp capture at the sample point of RES bit
  [0] RPED — RES bit Protocol exception disable
    0=Protocol exception event detection enabled; 1=Protocol exception event detection disabled
0x1318 CFDGCRCCFG — Global FD CRC Configuration register
  [0] NIE — Non ISO enable
    0=CAN FD frame format according to ISO 11898-1; 1=CAN FD frame format according to Bosch CAN FD Specification V1.0
0x131C CFDGLOCKK — Global Lock Key Register
  [15:0] LOCK wo — Lock Key
0x1320 CFDGLOTB reset 0x101 — Global OTB FIFO Configuration / Status Register
  [15:11] OTBMC ro — OTB FIFO Message Count
  [10] OTBMLT — OTB FIFO Message Lost
    0=No Message Lost in FIFO; 1=FIFO Message Lost
  [9] OTBFLL ro — OTB FIFO Full
    0=FIFO Not Full; 1=FIFO Full
  [8] OTBEMP ro — OTB FIFO Empty
    0=FIFO Not Empty; 1=FIFO Empty
  [0] OTBFE — OTB FIFO Enable
    0=FIFO disabled; 1=FIFO enabled
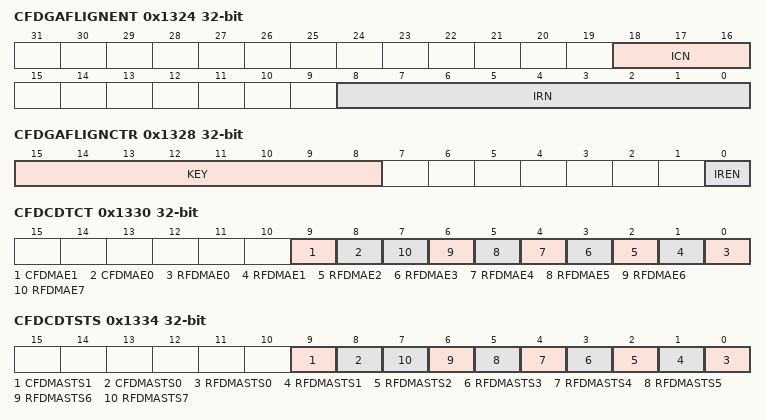
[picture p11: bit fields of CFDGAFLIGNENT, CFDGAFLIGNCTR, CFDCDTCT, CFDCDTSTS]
0x1324 CFDGAFLIGNENT — Global AFL Ignore Entry Register
  [18:16] ICN — Ignore Channel Number
  [8:0] IRN — Ignore Rule Number
0x1328 CFDGAFLIGNCTR — Global AFL Ignore Control Register
  [15:8] KEY wo — Key code
  [0] IREN — Ignore Rule Enable
    0=AFL entry number does not ignore; 1=AFL entry number ignores
0x1330 CFDCDTCT — DMA Transfer Control Register
  [9] CFDMAE1 — DMA Transfer Enable for Common FIFO 0 of channel 1
    0=DMA Transfer Request disabled for channel n; 1=DMA Transfer Request enabled for channel n
  [8] CFDMAE0 — DMA Transfer Enable for Common FIFO 0 of channel 0
    values as CFDMAE1
  [n] RFDMAE{n} (n=0..7) — DMA Transfer Enable for RXFIFO {n}
    0=DMA Transfer Request disabled; 1=DMA Transfer Request enabled
0x1334 CFDCDTSTS ro — DMA Transfer Status Register
  [all] fields
    0=DMA transfer stopped; 1=DMA transfer ongoing
  [9] CFDMASTS1 — DMA Transfer Status only for Common FIFO 0 of channel 1
  [8] CFDMASTS0 — DMA Transfer Status only for Common FIFO 0 of channel 0
  [n] RFDMASTS{n} (n=0..7) — DMA Transfer Status for RX FIFO {n}
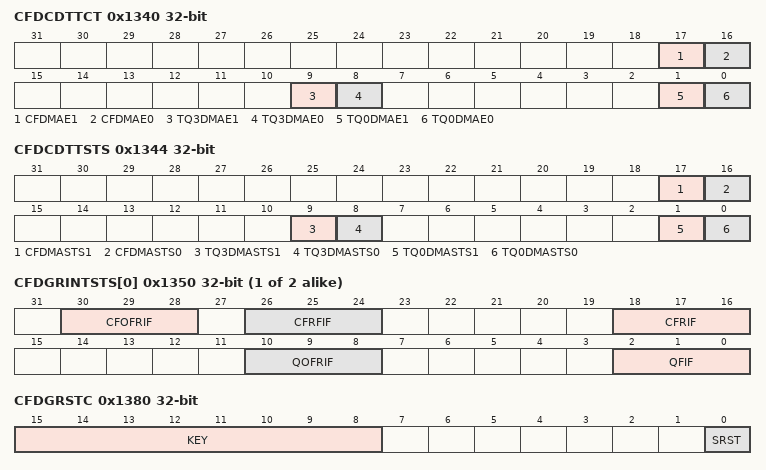
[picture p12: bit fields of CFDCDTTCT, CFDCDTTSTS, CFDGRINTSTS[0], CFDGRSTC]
0x1340 CFDCDTTCT — DMA TX Transfer Control Register
  [17] CFDMAE1 — DMA TX Transfer Enable for Common FIFO 2 of channel 1
    0=DMA TX Transfer Request disabled for channel n; 1=DMA TX Transfer Request enabled for channel n
  [16] CFDMAE0 — DMA TX Transfer Enable for Common FIFO 2 of channel 0
    values as CFDMAE1
  [9] TQ3DMAE1 — DMA TX Transfer Enable for TXQ 3 of channel 1
    0=DMA TX Transfer Request disabled; 1=DMA TX Transfer Request enabled
  [8] TQ3DMAE0 — DMA TX Transfer Enable for TXQ 3 of channel 0
    values as TQ3DMAE1
  [1] TQ0DMAE1 — DMA TX Transfer Enable for TXQ 0 of channel 1
    values as TQ3DMAE1
  [0] TQ0DMAE0 — DMA TX Transfer Enable for TXQ 0 of channel 0
    values as TQ3DMAE1
0x1344 CFDCDTTSTS — DMA TX Transfer Status Register
  [all] fields
    0=DMA transfer stopped; 1=DMA transfer enable
  [17] CFDMASTS1 ro — DMA TX Transfer Status only for Common FIFO 2 of channel 1
  [16] CFDMASTS0 ro — DMA TX Transfer Status only for Common FIFO 2 of channel 0
  [9] TQ3DMASTS1 ro — DMA TX Transfer Status for TXQ3 of channel 1
  [8] TQ3DMASTS0 ro — DMA TX Transfer Status for TXQ3 of channel 0
  [1] TQ0DMASTS1 ro — DMA TX Transfer Status for TXQ0 of channel 1
  [0] TQ0DMASTS0 ro — DMA TX Transfer Status for TXQ0 of channel 0
{0x1350+4i} CFDGRINTSTS[{i}] (i=0..1) — Global RX Interrupt Status Register
  [30:28] CFOFRIF ro — Common FIFO One Frame RX Interrupt Flag Channel n
    values as CFDCFOFRISTS.CFXOFRXIF
  [26:24] CFRFIF ro — Common FIFO FDC level Full Interrupt Flag Channel n
    0=Corresponding Common FIFO Full interrupt flag is not set; 1=Corresponding Common FIFO Full interrupt flag is set
  [18:16] CFRIF ro — Common FIFO RX Interrupt Flag Channel n
    values as CFDCFRISTS.CFXRXIF
  [10:8] QOFRIF ro — TXQ One Frame RX Interrupt Flag Channel n
    0=Corresponding TXQ One Frame RX interrupt flag is not set; 1=Corresponding TXQ One Frame RX interrupt flag is set
  [2:0] QFIF ro — TXQ Full Interrupt Flag Channel n
    0=Corresponding TXQ Full interrupt flag is not set; 1=Corresponding TXQ Full interrupt flag is set
0x1380 CFDGRSTC — Global SW reset Register
  [15:8] KEY wo — Key code
  [0] SRST — SW reset
    0=normal state; 1=SW reset state
{0x1400+0x20*i} CFDC2[{i}] (i=0..1) group — Channel Configuration Registers
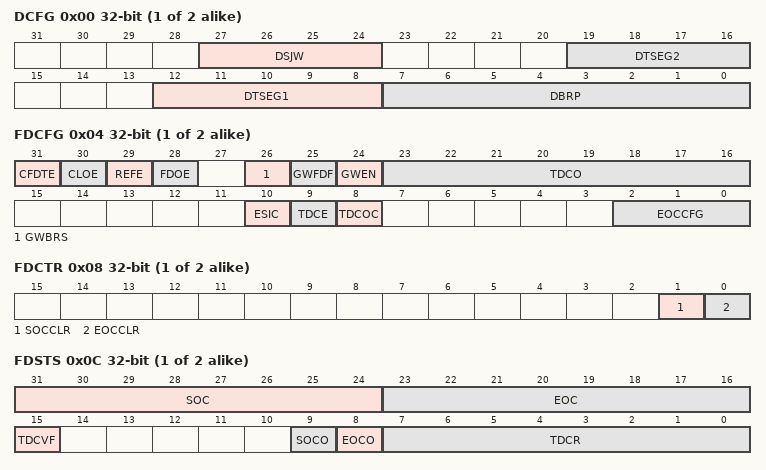
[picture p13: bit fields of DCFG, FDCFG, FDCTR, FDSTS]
  0x00 DCFG — Channel Data Bitrate Configuration Register
    [27:24] DSJW — Resynchronization Jump Width
    [19:16] DTSEG2 — Timing Segment 2
    [12:8] DTSEG1 — Timing Segment 1
    [7:0] DBRP — Channel Data Baud Rate Prescaler
  0x04 FDCFG — Channel CAN-FD Configuration Register
    [31] CFDTE — CAN-FD frame Distinction enable
      0=CAN-FD frame distinction disabled; 1=CAN-FD frame distinction enabled
    [30] CLOE — Classical CAN only enable
      0=Classical only mode disabled; 1=Classical only mode enabled
    [29] REFE — RX edge filter enable
      0=RX edge filter disabled; 1=RX edge filter enabled
    [28] FDOE — FD only enable
      0=FD only mode disabled; 1=FD only mode enabled
    [26] GWBRS — Gateway BRS configuration bit
      0=GW frame is transmitted with BRS = 0; 1=GW frame is transmitted with BRS = 1
    [25] GWFDF — Gateway FDF configuration bit
      0=GW frame is transmitted as Classical CAN frame; 1=GW frame is transmitted as CAN-FD frame 
    [24] GWEN — CAN2.0, CAN-FD <> CAN2.0, CAN-FD Multi Gateway Enable
      0=Multi Gateway Disabled; 1=Multi Gateway Enable
    [23:16] TDCO — Transceiver Delay Compensation Offset
    [10] ESIC — Error State Indication Configuration
      0=The ESI bit in the frame will be representing the Error state of the node itself; 1=The ESI bit in the frame will be representing the Error state of message buffer if the node itself is not in error passive. If the node is in Error Passive then the ESI bit will be driven by the node itself.
    [9] TDCE — Transceiver Delay Compensation Enable
      0=Transceiver Delay Compensation disabled; 1=Transceiver Delay Compensation enabled
    [8] TDCOC — Transceiver Delay Compensation Offset Configuration
      0=Measured + offset; 1=offset only
    [2:0] EOCCFG — Error Occurrence Counter Configuration
      0=All Transmitter or Receiver CAN Frames; 1=All Transmitter CAN Frames; 2=All Receiver CAN Frames; 4=Only Transmitter or Receiver CAN-FD Data-Phase (fast bits); 5=Only Transmitter CAN-FD Data-Phase (fast bits); 6=Only Receiver CAN-FD Data-Phase (fast bits)
  0x08 FDCTR — Channel CAN-FD Control Register
    [1] SOCCLR — Successful Occurrence Counter Clear
      0=No Successful Occurrence Counter clear; 1=Clear Successful Occurrence Counter
    [0] EOCCLR — Error Occurrence Counter Clear
      0=No Error Occurrence Counter clear; 1=Clear Error Occurrence Counter
  0x0C FDSTS — Channel CAN-FD Status Register
    [31:24] SOC ro — Successful occurrence counter register
    [23:16] EOC ro — Error occurrence counter register
    [15] TDCVF — Transceiver Delay Compensation Violation Flag
      0=Transceiver Delay Compensation Violation has not occurred; 1=Transceiver Delay Compensation Violation has occurred
    [9] SOCO — Successful occurrence counter overflow
      0=Successful occurrence counter has not overflowed; 1=Successful occurrence counter has overflowed
    [8] EOCO — Error occurrence counter overflow
      0=Error occurrence counter has not overflowed; 1=Error occurrence counter has overflowed
    [7:0] TDCR ro — Transceiver Delay Compensation Result
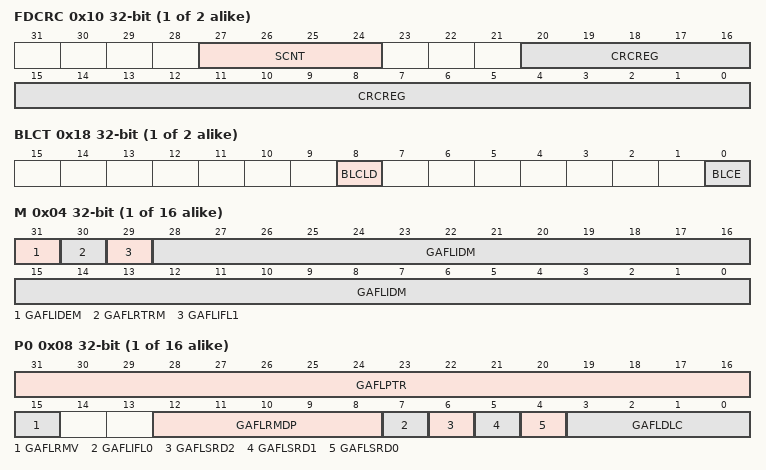
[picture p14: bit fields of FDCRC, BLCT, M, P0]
  0x10 FDCRC — Channel CAN-FD CRC Register
    [27:24] SCNT ro — Stuff bit count
    [20:0] CRCREG ro — CRC Register value
  0x18 BLCT — Channel Bus load Control Register
    [8] BLCLD wo — BUS Load counter load
    [0] BLCE — BUS Load counter Enable
      0=BUS Load counter disable; 1=BUS Load counter enable
  0x1C BLSTS — Channel Bus load Status Register
    [31:3] BLC ro — BUS Load counter Status
{0x1800+0x10*i} CFDGAFL[{i}] (i=0..15) group — Global Acceptance Filter List Registers
  0x00 ID — Global Acceptance Filter List ID Registers
    [31] GAFLIDE — Global Acceptance Filter List Entry IDE Field
      0=Standard Identifier of Rule entry ID is valid for acceptance filtering; 1=Extended Identifier of Rule entry ID is valid for acceptance filtering
    [30] GAFLRTR — Global Acceptance Filter List Entry RTR Field
      0=Data Frame; 1=Remote Frame
    [29] GAFLLB — Global Acceptance Filter List Entry Loopback Configuration
      0=Global Acceptance Filter List entry ID for acceptance filtering has attribute RX; 1=Global Acceptance Filter List entry ID for acceptance filtering has attribute TX
    [28:0] GAFLID — Global Acceptance Filter List Entry ID Field
  0x04 M — Global Acceptance Filter List Mask Registers
    [31] GAFLIDEM — Global Acceptance Filter List IDE Mask
      0=IDE bit is not considered for ID matching; 1=IDE bit is considered for ID matching
    [30] GAFLRTRM — Global Acceptance Filter List Entry RTR Mask
      0=RTR bit is not considered for ID matching; 1=RTR bit is considered for ID matching
    [29] GAFLIFL1 — Global Acceptance Filter List Information Label 1
    [28:0] GAFLIDM — Global Acceptance Filter List ID Mask Field
  0x08 P0 — Global Acceptance Filter List Pointer 0 Registers
    [31:16] GAFLPTR — Global Acceptance Filter List Pointer Field
    [15] GAFLRMV — Global Acceptance Filter List RX Message Buffer Valid
      0=Global Acceptance Filter List Single Message Buffer Direction Pointer is invalid; 1=Global Acceptance Filter List Single Message Buffer Direction Pointer is valid
    [12:8] GAFLRMDP — Global Acceptance Filter List RX Message Buffer Direction Pointer
    [7] GAFLIFL0 — Global Acceptance Filter List Information Label 0
    [6] GAFLSRD2 — Global Acceptance Filter List Select Routing destination 2
      0=Routing target is CFIFO2; 1=Routing target is TX Queue 2 instead of CFIFO2
    [5] GAFLSRD1 — Global Acceptance Filter List Select Routing destination 1
      0=Routing target is CFIFO1; 1=Routing target is TX Queue 1 instead of CFIFO1
    [4] GAFLSRD0 — Global Acceptance Filter List Select Routing destination 0
      0=Routing target is CFIFO0; 1=Routing target is TX Queue 0 instead of CFIFO0
    [3:0] GAFLDLC — Global Acceptance Filter List DLC Field
  0x0C P1 — Global Acceptance Filter List Pointer 1 Registers
    [13:0] GAFLFDP — Global Acceptance Filter List FIFO Direction Pointer
{0x2000+0x80*i} CFDRM[{i}] (i=0..31) group — RX Message Buffer Access Registers
  0x00 ID ro — RX Message Buffer ID Register
    [31] RMIDE — RX Message Buffer IDE Bit
      0=STD-ID is stored; 1=EXT-ID is stored
    [30] RMRTR — RX Message Buffer RTR Frame
      0=Data frame; 1=Remote frame
    [28:0] RMID — RX Message Buffer ID Field
  0x04 PTR ro — RX Message Buffer Pointer Register
    [31:28] RMDLC — RX Message Buffer DLC Field
    [15:0] RMTS — RX Message Buffer Timestamp Field
  0x08 FDSTS ro — RX Message Buffer CAN-FD Status Register
    [31:16] RMPTR — RX Message Buffer Pointer Field
    [9:8] RMIFL — RX Message Buffer Information Label Field
    [2] RMFDF — CAN FD Format bit
      0=Non CAN-FD frame received; 1=CAN-FD frame received
    [1] RMBRS — Bit Rate Switch bit
      0=CAN-FD frame received with no bit rate switch; 1=CAN-FD frame received with bit rate switch
    [0] RMESI — Error State Indicator bit
      0=CAN-FD frame received from error active node; 1=CAN-FD frame received from error passive node
  {0xC+j} DF[{j}] (j=0..63) 8-bit ro — RX Message Buffer Data Field Registers
    [7:0] RMDB — RX Message Buffer Data Byte
{0x6000+0x80*i} CFDRF[{i}] (i=0..7) group — RX FIFO Access Registers
  0x00 ID ro — RX FIFO Access ID Register
    [31] RFIDE — RX FIFO Buffer IDE Bit
      0=STD-ID is stored; 1=EXT-ID is stored
    [30] RFRTR — RX FIFO Buffer RTR Frame
      0=Data frame; 1=Remote frame
    [28:0] RFID — RX FIFO Buffer ID Field
  0x04 PTR ro — RX FIFO Access Pointer Register
    [31:28] RFDLC — RX FIFO Buffer DLC Field
    [15:0] RFTS — RX FIFO Timestamp Field
  0x08 FDSTS ro — RX FIFO Access CAN-FD Status Register
    [31:16] RFPTR — RX FIFO Buffer Pointer Field
    [9:8] RFIFL — RX FIFO Buffer Information Label Field
    [2] RFFDF — CAN FD Format bit
      0=Non CAN-FD frame received; 1=CAN-FD frame received
    [1] RFBRS — Bit Rate Switch bit
      values as CFDRM[0].FDSTS.RMBRS
    [0] RFESI — Error State Indicator bit
      values as CFDRM[0].FDSTS.RMESI
  {0xC+j} DF[{j}] (j=0..63) 8-bit ro — RX FIFO Access Data Field Registers
    [7:0] RFDB — RX FIFO Buffer Data Byte
{0x6420+0x80*i} CFDCF[{i}] (i=0..4) group — Common FIFO Access Registers
  0x00 ID ro — Common FIFO Access ID Register
    [31] CFIDE — Common FIFO Buffer IDE Bit
      0=STD-ID is stored; 1=EXT-ID is stored
    [30] CFRTR — Common FIFO Buffer RTR Frame
      0=Data frame; 1=Remote frame
    [28:0] CFID — Common FIFO Buffer ID Field
  0x04 PTR ro — Common FIFO Access Pointer Register
    [31:28] CFDLC — Common FIFO Buffer DLC Field
    [15:0] CFTS — Common FIFO Timestamp Field
  0x08 FDSTS ro — Common FIFO Access CAN-FD Status Register
    [31:16] CFPTR — Common FIFO Buffer Pointer Field
    [9:8] CFIFL — Common FIFO Buffer Information Label Field
    [2] CFFDF — CAN FD Format bit
      0=Non CAN-FD frame received; 1=CAN-FD frame received
    [1] CFBRS — Bit Rate Switch bit
      values as CFDRM[0].FDSTS.RMBRS
    [0] CFESI — Error State Indicator bit
      values as CFDRM[0].FDSTS.RMESI
  {0xC+j} DF[{j}] (j=0..63) 8-bit ro — Common FIFO Access Data Field Registers
    [7:0] CFDB — Common FIFO Buffer Data Byte
{0x8000+8i} CFDTHL[{i}] (i=0..1) group — Channel TX History List
  0x00 ACC0 ro — Channel TX History List Access Registers 0
    [31:16] TMTS — Transmit Timestamp
    [15] TGW — Transmit Gateway Buffer indication
      0=not transmission from Gateway; 1=transmission from Gateway
    [9:3] BN — Buffer No.
    [2:0] BT — Buffer Type
      1=Flat TX Message Buffer; 2=TX FIFO MB No and GW FIFO MB No; 4=TX Queue MB No
  0x04 ACC1 — Channel TX History List Access Registers 1
    [17:16] TIFL ro — Transmit Information Label
    [15:0] TID ro — Transmit ID
{0x8400+4i} CFDRPGACC[{i}] (i=0..63) — RAM Test Page Access Registers
  [31:0] RDTA — RAM Data Test Access
{0x10000+0x80*i} CFDTM[{i}] (i=0..31) group — TX Message Buffer Access Registers
  0x00 ID — TX Message Buffer ID Register
    [31] TMIDE — TX Message Buffer IDE Bit
      0=STD-ID is stored; 1=EXT-ID is stored
    [30] TMRTR — TX Message Buffer RTR Frame
      0=Data frame; 1=Remote frame
    [28:0] TMID — TX Message Buffer ID Field
  0x04 PTR — TX Message Buffer Pointer Register
    [31:28] TMDLC — TX Message Buffer DLC Field
    [15:0] TMTS — TX Message Buffer Timestamp Field
  0x08 FDSTS — TX Message Buffer CAN-FD Status Register
    [31:16] TMPTR — TX Message Buffer Pointer Field
    [9:8] TMIFL — TX Message Buffer Information Label Field
    [2] TMFDF — CAN FD Format bit
      0=Non CAN-FD frame received; 1=CAN-FD frame received
    [1] TMBRS — Bit Rate Switch bit
      values as CFDRM[0].FDSTS.RMBRS
    [0] TMESI — Error State Indicator bit
      values as CFDRM[0].FDSTS.RMESI
  {0xC+j} DF[{j}] (j=0..63) 8-bit — TX Message Buffer Data Field Registers
    [7:0] TMDB — TX Message Buffer Data Byte
